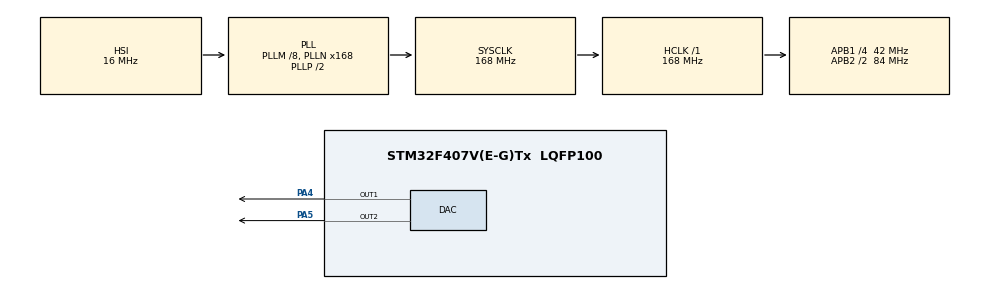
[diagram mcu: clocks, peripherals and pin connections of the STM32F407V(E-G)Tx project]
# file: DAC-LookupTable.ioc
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DAC.DAC_Trigger=DAC_TRIGGER_T6_TRGO
DAC.DAC_Trigger2=DAC_TRIGGER_T7_TRGO
Dma.DAC1.0.Direction=DMA_MEMORY_TO_PERIPH
Dma.DAC1.0.FIFOMode=DMA_FIFOMODE_DISABLE
Dma.DAC1.0.Instance=DMA1_Stream5
Dma.DAC1.0.MemDataAlignment=DMA_MDATAALIGN_HALFWORD
Dma.DAC1.0.MemInc=DMA_MINC_ENABLE
Dma.DAC1.0.Mode=DMA_CIRCULAR
Dma.DAC1.0.PeriphDataAlignment=DMA_PDATAALIGN_HALFWORD
Dma.DAC1.0.PeriphInc=DMA_PINC_DISABLE
Dma.DAC1.0.Priority=DMA_PRIORITY_LOW
Dma.DAC2.1.Direction=DMA_MEMORY_TO_PERIPH
Dma.DAC2.1.FIFOMode=DMA_FIFOMODE_DISABLE
Dma.DAC2.1.Instance=DMA1_Stream6
Dma.DAC2.1.MemDataAlignment=DMA_MDATAALIGN_HALFWORD
Dma.DAC2.1.MemInc=DMA_MINC_ENABLE
Dma.DAC2.1.Mode=DMA_CIRCULAR
Dma.DAC2.1.PeriphDataAlignment=DMA_PDATAALIGN_HALFWORD
Dma.DAC2.1.PeriphInc=DMA_PINC_DISABLE
Dma.DAC2.1.Priority=DMA_PRIORITY_LOW
Dma.Request0=DAC1
Dma.Request1=DAC2
Mcu.Family=STM32F4
Mcu.Name=STM32F407V(E-G)Tx
Mcu.Package=LQFP100
NVIC.DMA1_Stream5_IRQn=true\:0\:0\:false\:false\:true\:false\:true
NVIC.DMA1_Stream6_IRQn=true\:0\:0\:false\:false\:true\:false\:true
NVIC.PriorityGroup=NVIC_PRIORITYGROUP_4
NVIC.TIM6_DAC_IRQn=true\:0\:0\:false\:false\:true\:true\:true
PA4.Signal=COMP_DAC1_group
PA5.Signal=COMP_DAC2_group
ProjectManager.HeapSize=0x200
ProjectManager.StackSize=0x400
ProjectManager.TargetToolchain=MDK-ARM V5.27
RCC.48MHZClocksFreq_Value=84000000
RCC.AHBFreq_Value=168000000
RCC.APB1CLKDivider=RCC_HCLK_DIV4
RCC.APB1Freq_Value=42000000
RCC.APB1TimFreq_Value=84000000
RCC.APB2CLKDivider=RCC_HCLK_DIV2
RCC.APB2Freq_Value=84000000
RCC.APB2TimFreq_Value=168000000
RCC.CortexFreq_Value=168000000
RCC.HCLKFreq_Value=168000000
RCC.HSE_VALUE=25000000
RCC.HSI_VALUE=16000000
RCC.LSE_VALUE=32768
RCC.PLLM=8
RCC.PLLN=168
RCC.SYSCLKFreq_VALUE=168000000
RCC.SYSCLKSource=RCC_SYSCLKSOURCE_PLLCLK
RCC.VCOOutputFreq_Value=336000000
SH.COMP_DAC1_group.0=DAC_OUT1,DAC_OUT1
SH.COMP_DAC2_group.0=DAC_OUT2,DAC_OUT2
TIM6.Period=10-1
TIM6.Prescaler=525-1
TIM6.TIM_MasterOutputTrigger=TIM_TRGO_UPDATE
TIM7.Period=10-1
TIM7.Prescaler=525-1
TIM7.TIM_MasterOutputTrigger=TIM_TRGO_UPDATE
VP_TIM6_VS_ClockSourceINT.Mode=Enable_Timer
VP_TIM7_VS_ClockSourceINT.Mode=Enable_Timer
board=custom

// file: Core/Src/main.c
/* USER CODE BEGIN Header */
/**
  ******************************************************************************
  * @file           : main.c
  * @brief          : Main program body
  ******************************************************************************
  * @attention
  *
  * <h2><center>&copy; Copyright (c) 2023 STMicroelectronics.
  * All rights reserved.</center></h2>
  *
  * This software component is licensed by ST under BSD 3-Clause license,
  * the "License"; You may not use this file except in compliance with the
  * License. You may obtain a copy of the License at:
  *                        opensource.org/licenses/BSD-3-Clause
  *
  ******************************************************************************
  */
/* USER CODE END Header */
#include "main.h"
#include "dac.h"
#include "dma.h"
#include "tim.h"
#include "gpio.h"

/* USER CODE BEGIN PTD */
typedef struct {
  const uint16_t*       Wave;
  uint16_t              Len;
} DAC_Output;
/* USER CODE END PTD */

/* USER CODE BEGIN PD */
#define  WAVE_1HZ_CARRIER_FREQ    16000
#define  WAVE_1HZ_LEN             16000

#define  WAVE_5HZ_CARRIER_FREQ    16000
#define  WAVE_5HZ_LEN             3200

/* USER CODE END PD */

/* USER CODE BEGIN PV */
extern const uint16_t WAVE_1HZ[WAVE_1HZ_LEN];
extern const uint16_t WAVE_5HZ[WAVE_5HZ_LEN];

static const DAC_Output DAC_OUTPUT[] = {
  {WAVE_1HZ, WAVE_1HZ_LEN},
  {WAVE_5HZ, WAVE_5HZ_LEN},
};
/* USER CODE END PV */

void SystemClock_Config(void);

int main(void)
{
  /* USER CODE BEGIN 1 */
  uint8_t state = 0;
  /* USER CODE END 1 */

  /* MCU Configuration--------------------------------------------------------*/

  /* Reset of all peripherals, Initializes the Flash interface and the Systick. */
  HAL_Init();

  /* Configure the system clock */
  SystemClock_Config();

  /* Initialize all configured peripherals */
  MX_GPIO_Init();
  MX_DMA_Init();
  MX_DAC_Init();
  MX_TIM6_Init();
  MX_TIM7_Init();
  /* USER CODE BEGIN 2 */
  HAL_DAC_Start_DMA(&hdac, DAC_CHANNEL_1, (uint32_t*) DAC_OUTPUT[state].Wave, DAC_OUTPUT[state].Len, DAC_ALIGN_12B_R);
  HAL_DAC_Start_DMA(&hdac, DAC_CHANNEL_2, (uint32_t*) DAC_OUTPUT[!state].Wave, DAC_OUTPUT[!state].Len, DAC_ALIGN_12B_R);

  HAL_TIM_Base_Start(&htim6);
  HAL_TIM_Base_Start(&htim7);

  /* USER CODE END 2 */

  /* Infinite loop */
  /* USER CODE BEGIN WHILE */
  while (1)
  {
    HAL_Delay(3000);
    state = !state;

    hdac.DMA_Handle1->Instance->CR &= ~DMA_SxCR_EN;
    hdac.DMA_Handle1->Instance->M0AR = (uint32_t) DAC_OUTPUT[state].Wave;
    hdac.DMA_Handle1->Instance->NDTR = (uint32_t) DAC_OUTPUT[state].Len;
    hdac.DMA_Handle1->Instance->CR |= DMA_SxCR_EN;

    hdac.DMA_Handle2->Instance->CR &= ~DMA_SxCR_EN;
    hdac.DMA_Handle2->Instance->M0AR = (uint32_t) DAC_OUTPUT[!state].Wave;
    hdac.DMA_Handle2->Instance->NDTR = (uint32_t) DAC_OUTPUT[!state].Len;
    hdac.DMA_Handle2->Instance->CR |= DMA_SxCR_EN;

    /* USER CODE END WHILE */

  }
}

void SystemClock_Config(void)
{
  RCC_OscInitTypeDef RCC_OscInitStruct = {0};
  RCC_ClkInitTypeDef RCC_ClkInitStruct = {0};

  /** Configure the main internal regulator output voltage
  */
  __HAL_RCC_PWR_CLK_ENABLE();
  __HAL_PWR_VOLTAGESCALING_CONFIG(PWR_REGULATOR_VOLTAGE_SCALE1);
  /** Initializes the RCC Oscillators according to the specified parameters
  * in the RCC_OscInitTypeDef structure.
  */
  RCC_OscInitStruct.OscillatorType = RCC_OSCILLATORTYPE_HSI;
  RCC_OscInitStruct.HSIState = RCC_HSI_ON;
  RCC_OscInitStruct.HSICalibrationValue = RCC_HSICALIBRATION_DEFAULT;
  RCC_OscInitStruct.PLL.PLLState = RCC_PLL_ON;
  RCC_OscInitStruct.PLL.PLLSource = RCC_PLLSOURCE_HSI;
  RCC_OscInitStruct.PLL.PLLM = 8;
  RCC_OscInitStruct.PLL.PLLN = 168;
  RCC_OscInitStruct.PLL.PLLP = RCC_PLLP_DIV2;
  RCC_OscInitStruct.PLL.PLLQ = 4;
  if (HAL_RCC_OscConfig(&RCC_OscInitStruct) != HAL_OK)
  {
    Error_Handler();
  }
  /** Initializes the CPU, AHB and APB buses clocks
  */
  RCC_ClkInitStruct.ClockType = RCC_CLOCKTYPE_HCLK|RCC_CLOCKTYPE_SYSCLK
                              |RCC_CLOCKTYPE_PCLK1|RCC_CLOCKTYPE_PCLK2;
  RCC_ClkInitStruct.SYSCLKSource = RCC_SYSCLKSOURCE_PLLCLK;
  RCC_ClkInitStruct.AHBCLKDivider = RCC_SYSCLK_DIV1;
  RCC_ClkInitStruct.APB1CLKDivider = RCC_HCLK_DIV4;
  RCC_ClkInitStruct.APB2CLKDivider = RCC_HCLK_DIV2;

  if (HAL_RCC_ClockConfig(&RCC_ClkInitStruct, FLASH_LATENCY_5) != HAL_OK)
  {
    Error_Handler();
  }
}

void Error_Handler(void)
{
  __disable_irq();
  while (1)
  {
  }
}

/************************ (C) COPYRIGHT STMicroelectronics *****END OF FILE****/
